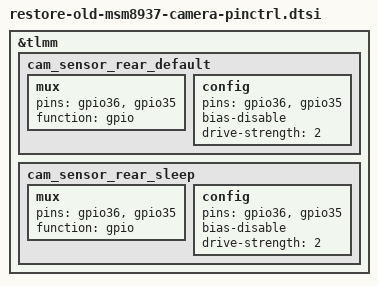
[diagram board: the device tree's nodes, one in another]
&tlmm {
	/delete-node/ cam_sensor_rear_reset;
	/delete-node/ cam_sensor_rear_reset_sleep;
	/delete-node/ cam_sensor_front1_default;
	/delete-node/ cam_sensor_front1_sleep;
};

&tlmm {
	cam_sensor_rear_default: cam_sensor_rear_default {
		/* RESET, STANDBY */
		mux {
			pins = "gpio36", "gpio35";
			function = "gpio";
		};

		config {
			pins = "gpio36","gpio35";
			bias-disable; /* No PULL */
			drive-strength = <2>; /* 2 MA */
		};
	};

	cam_sensor_rear_sleep: cam_sensor_rear_sleep {
		/* RESET, STANDBY */
		mux {
			pins = "gpio36","gpio35";
			function = "gpio";
		};

		config {
			pins = "gpio36","gpio35";
			bias-disable; /* No PULL */
			drive-strength = <2>; /* 2 MA */
		};
	};
};
